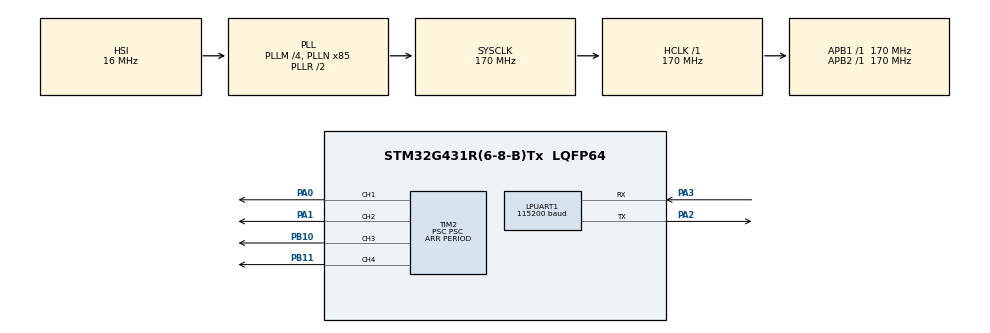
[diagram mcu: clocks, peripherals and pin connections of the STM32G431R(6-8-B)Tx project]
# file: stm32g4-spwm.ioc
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Dma.LPUART1_RX.1.Direction=DMA_PERIPH_TO_MEMORY
Dma.LPUART1_RX.1.EventEnable=DISABLE
Dma.LPUART1_RX.1.Instance=DMA1_Channel2
Dma.LPUART1_RX.1.MemDataAlignment=DMA_MDATAALIGN_BYTE
Dma.LPUART1_RX.1.MemInc=DMA_MINC_ENABLE
Dma.LPUART1_RX.1.Mode=DMA_NORMAL
Dma.LPUART1_RX.1.PeriphDataAlignment=DMA_PDATAALIGN_BYTE
Dma.LPUART1_RX.1.PeriphInc=DMA_PINC_DISABLE
Dma.LPUART1_RX.1.Polarity=HAL_DMAMUX_REQ_GEN_RISING
Dma.LPUART1_RX.1.Priority=DMA_PRIORITY_MEDIUM
Dma.LPUART1_RX.1.RequestNumber=1
Dma.LPUART1_RX.1.SignalID=NONE
Dma.LPUART1_RX.1.SyncEnable=DISABLE
Dma.LPUART1_RX.1.SyncPolarity=HAL_DMAMUX_SYNC_NO_EVENT
Dma.LPUART1_RX.1.SyncRequestNumber=1
Dma.LPUART1_RX.1.SyncSignalID=NONE
Dma.LPUART1_TX.2.Direction=DMA_MEMORY_TO_PERIPH
Dma.LPUART1_TX.2.EventEnable=DISABLE
Dma.LPUART1_TX.2.Instance=DMA1_Channel3
Dma.LPUART1_TX.2.MemDataAlignment=DMA_MDATAALIGN_BYTE
Dma.LPUART1_TX.2.MemInc=DMA_MINC_ENABLE
Dma.LPUART1_TX.2.Mode=DMA_NORMAL
Dma.LPUART1_TX.2.PeriphDataAlignment=DMA_PDATAALIGN_BYTE
Dma.LPUART1_TX.2.PeriphInc=DMA_PINC_DISABLE
Dma.LPUART1_TX.2.Polarity=HAL_DMAMUX_REQ_GEN_RISING
Dma.LPUART1_TX.2.Priority=DMA_PRIORITY_MEDIUM
Dma.LPUART1_TX.2.RequestNumber=1
Dma.LPUART1_TX.2.SignalID=NONE
Dma.LPUART1_TX.2.SyncEnable=DISABLE
Dma.LPUART1_TX.2.SyncPolarity=HAL_DMAMUX_SYNC_NO_EVENT
Dma.LPUART1_TX.2.SyncRequestNumber=1
Dma.LPUART1_TX.2.SyncSignalID=NONE
Dma.Request0=TIM2_UP
Dma.Request1=LPUART1_RX
Dma.Request2=LPUART1_TX
Dma.TIM2_UP.0.Direction=DMA_MEMORY_TO_PERIPH
Dma.TIM2_UP.0.EventEnable=DISABLE
Dma.TIM2_UP.0.Instance=DMA1_Channel1
Dma.TIM2_UP.0.MemDataAlignment=DMA_MDATAALIGN_WORD
Dma.TIM2_UP.0.MemInc=DMA_MINC_ENABLE
Dma.TIM2_UP.0.Mode=DMA_CIRCULAR
Dma.TIM2_UP.0.PeriphDataAlignment=DMA_PDATAALIGN_WORD
Dma.TIM2_UP.0.PeriphInc=DMA_PINC_DISABLE
Dma.TIM2_UP.0.Polarity=HAL_DMAMUX_REQ_GEN_RISING
Dma.TIM2_UP.0.Priority=DMA_PRIORITY_MEDIUM
Dma.TIM2_UP.0.RequestNumber=1
Dma.TIM2_UP.0.SignalID=NONE
Dma.TIM2_UP.0.SyncEnable=DISABLE
Dma.TIM2_UP.0.SyncPolarity=HAL_DMAMUX_SYNC_NO_EVENT
Dma.TIM2_UP.0.SyncRequestNumber=1
Dma.TIM2_UP.0.SyncSignalID=NONE
LPUART1.BaudRate=115200
Mcu.Family=STM32G4
Mcu.Name=STM32G431R(6-8-B)Tx
Mcu.Package=LQFP64
NVIC.DMA1_Channel1_IRQn=true\:0\:0\:false\:false\:true\:false\:true\:true
NVIC.DMA1_Channel2_IRQn=true\:0\:0\:false\:false\:true\:false\:true\:true
NVIC.DMA1_Channel3_IRQn=true\:0\:0\:false\:false\:true\:false\:true\:true
NVIC.LPUART1_IRQn=true\:0\:0\:false\:false\:true\:true\:true\:true
NVIC.PriorityGroup=NVIC_PRIORITYGROUP_4
NVIC.TIM2_IRQn=true\:0\:0\:false\:false\:true\:true\:true\:true
PA0.GPIO_Speed=GPIO_SPEED_FREQ_HIGH
PA0.Signal=S_TIM2_CH1
PA1.GPIO_Speed=GPIO_SPEED_FREQ_HIGH
PA1.Signal=S_TIM2_CH2
PA13.Mode=Serial_Wire
PA13.Signal=SYS_JTMS-SWDIO
PA14.Mode=Serial_Wire
PA14.Signal=SYS_JTCK-SWCLK
PA2.GPIO_Speed=GPIO_SPEED_FREQ_MEDIUM
PA2.Mode=Asynchronous
PA2.Signal=LPUART1_TX
PA3.GPIO_Speed=GPIO_SPEED_FREQ_MEDIUM
PA3.Mode=Asynchronous
PA3.Signal=LPUART1_RX
PB10.GPIO_Speed=GPIO_SPEED_FREQ_HIGH
PB10.Signal=S_TIM2_CH3
PB11.GPIO_Speed=GPIO_SPEED_FREQ_HIGH
PB11.Signal=S_TIM2_CH4
PF0-OSC_IN.Mode=HSE-External-Oscillator
PF0-OSC_IN.Signal=RCC_OSC_IN
PF1-OSC_OUT.Mode=HSE-External-Oscillator
PF1-OSC_OUT.Signal=RCC_OSC_OUT
ProjectManager.HeapSize=0x200
ProjectManager.StackSize=0x400
ProjectManager.TargetToolchain=CMake
RCC.ADC12Freq_Value=170000000
RCC.AHBFreq_Value=170000000
RCC.APB1Freq_Value=170000000
RCC.APB1TimFreq_Value=170000000
RCC.APB2Freq_Value=170000000
RCC.APB2TimFreq_Value=170000000
RCC.CortexFreq_Value=170000000
RCC.EXTERNAL_CLOCK_VALUE=12288000
RCC.HCLKFreq_Value=170000000
RCC.HSE_VALUE=8000000
RCC.HSI48_VALUE=48000000
RCC.HSI_VALUE=16000000
RCC.LSE_VALUE=32768
RCC.PLLM=RCC_PLLM_DIV4
RCC.PLLN=85
RCC.SYSCLKFreq_VALUE=170000000
RCC.SYSCLKSource=RCC_SYSCLKSOURCE_PLLCLK
RCC.USBFreq_Value=170000000
RCC.VCOOutputFreq_Value=340000000
SH.S_TIM2_CH1.0=TIM2_CH1,PWM Generation1 CH1
SH.S_TIM2_CH2.0=TIM2_CH2,PWM Generation2 CH2
SH.S_TIM2_CH3.0=TIM2_CH3,PWM Generation3 CH3
SH.S_TIM2_CH4.0=TIM2_CH4,PWM Generation4 CH4
TIM2.Channel-PWM\ Generation1\ CH1=TIM_CHANNEL_1
TIM2.Channel-PWM\ Generation2\ CH2=TIM_CHANNEL_2
TIM2.Channel-PWM\ Generation3\ CH3=TIM_CHANNEL_3
TIM2.Channel-PWM\ Generation4\ CH4=TIM_CHANNEL_4
TIM2.OCFastMode_PWM-PWM\ Generation1\ CH1=TIM_OCFAST_ENABLE
TIM2.OCFastMode_PWM-PWM\ Generation2\ CH2=TIM_OCFAST_ENABLE
TIM2.OCFastMode_PWM-PWM\ Generation3\ CH3=TIM_OCFAST_ENABLE
TIM2.OCFastMode_PWM-PWM\ Generation4\ CH4=TIM_OCFAST_ENABLE
TIM2.PeriodNoDither=PERIOD
TIM2.Prescaler=PSC
VP_SYS_VS_DBSignals.Mode=DisableDeadBatterySignals
VP_TIM2_VS_ClockSourceINT.Mode=Internal
board=custom

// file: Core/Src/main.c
/* USER CODE BEGIN Header */
/**
  ******************************************************************************
  * @file           : main.c
  * @brief          : Main program body
  ******************************************************************************
  * @attention
  *
  * Copyright (c) 2026 STMicroelectronics.
  * All rights reserved.
  *
  * This software is licensed under terms that can be found in the LICENSE file
  * in the root directory of this software component.
  * If no LICENSE file comes with this software, it is provided AS-IS.
  *
  ******************************************************************************
  */
/* USER CODE END Header */
#include "main.h"

/* USER CODE BEGIN PTD */
#define PSC 1
#define PERIOD 100

/* USER CODE END PTD */

UART_HandleTypeDef hlpuart1;
DMA_HandleTypeDef hdma_lpuart1_rx;
DMA_HandleTypeDef hdma_lpuart1_tx;

TIM_HandleTypeDef htim2;
DMA_HandleTypeDef hdma_tim2_up;

void SystemClock_Config(void);
static void MX_GPIO_Init(void);
static void MX_DMA_Init(void);
static void MX_TIM2_Init(void);
static void MX_LPUART1_UART_Init(void);

int main(void)
{

  /* MCU Configuration--------------------------------------------------------*/

  /* Reset of all peripherals, Initializes the Flash interface and the Systick. */
  HAL_Init();

  /* Configure the system clock */
  SystemClock_Config();

  /* Initialize all configured peripherals */
  MX_GPIO_Init();
  MX_DMA_Init();
  MX_TIM2_Init();
  MX_LPUART1_UART_Init();

  /* Infinite loop */
  while (1)
  {

  }
}

void SystemClock_Config(void)
{
  RCC_OscInitTypeDef RCC_OscInitStruct = {0};
  RCC_ClkInitTypeDef RCC_ClkInitStruct = {0};

  /** Configure the main internal regulator output voltage
  */
  HAL_PWREx_ControlVoltageScaling(PWR_REGULATOR_VOLTAGE_SCALE1_BOOST);

  /** Initializes the RCC Oscillators according to the specified parameters
  * in the RCC_OscInitTypeDef structure.
  */
  RCC_OscInitStruct.OscillatorType = RCC_OSCILLATORTYPE_HSI;
  RCC_OscInitStruct.HSIState = RCC_HSI_ON;
  RCC_OscInitStruct.HSICalibrationValue = RCC_HSICALIBRATION_DEFAULT;
  RCC_OscInitStruct.PLL.PLLState = RCC_PLL_ON;
  RCC_OscInitStruct.PLL.PLLSource = RCC_PLLSOURCE_HSI;
  RCC_OscInitStruct.PLL.PLLM = RCC_PLLM_DIV4;
  RCC_OscInitStruct.PLL.PLLN = 85;
  RCC_OscInitStruct.PLL.PLLP = RCC_PLLP_DIV2;
  RCC_OscInitStruct.PLL.PLLQ = RCC_PLLQ_DIV2;
  RCC_OscInitStruct.PLL.PLLR = RCC_PLLR_DIV2;
  if (HAL_RCC_OscConfig(&RCC_OscInitStruct) != HAL_OK)
  {
    Error_Handler();
  }

  /** Initializes the CPU, AHB and APB buses clocks
  */
  RCC_ClkInitStruct.ClockType = RCC_CLOCKTYPE_HCLK|RCC_CLOCKTYPE_SYSCLK
                              |RCC_CLOCKTYPE_PCLK1|RCC_CLOCKTYPE_PCLK2;
  RCC_ClkInitStruct.SYSCLKSource = RCC_SYSCLKSOURCE_PLLCLK;
  RCC_ClkInitStruct.AHBCLKDivider = RCC_SYSCLK_DIV1;
  RCC_ClkInitStruct.APB1CLKDivider = RCC_HCLK_DIV1;
  RCC_ClkInitStruct.APB2CLKDivider = RCC_HCLK_DIV1;

  if (HAL_RCC_ClockConfig(&RCC_ClkInitStruct, FLASH_LATENCY_4) != HAL_OK)
  {
    Error_Handler();
  }
}

static void MX_LPUART1_UART_Init(void)
{

  hlpuart1.Instance = LPUART1;
  hlpuart1.Init.BaudRate = 115200;
  hlpuart1.Init.WordLength = UART_WORDLENGTH_8B;
  hlpuart1.Init.StopBits = UART_STOPBITS_1;
  hlpuart1.Init.Parity = UART_PARITY_NONE;
  hlpuart1.Init.Mode = UART_MODE_TX_RX;
  hlpuart1.Init.HwFlowCtl = UART_HWCONTROL_NONE;
  hlpuart1.Init.OneBitSampling = UART_ONE_BIT_SAMPLE_DISABLE;
  hlpuart1.Init.ClockPrescaler = UART_PRESCALER_DIV1;
  hlpuart1.AdvancedInit.AdvFeatureInit = UART_ADVFEATURE_NO_INIT;
  if (HAL_UART_Init(&hlpuart1) != HAL_OK)
  {
    Error_Handler();
  }
  if (HAL_UARTEx_SetTxFifoThreshold(&hlpuart1, UART_TXFIFO_THRESHOLD_1_8) != HAL_OK)
  {
    Error_Handler();
  }
  if (HAL_UARTEx_SetRxFifoThreshold(&hlpuart1, UART_RXFIFO_THRESHOLD_1_8) != HAL_OK)
  {
    Error_Handler();
  }
  if (HAL_UARTEx_DisableFifoMode(&hlpuart1) != HAL_OK)
  {
    Error_Handler();
  }

}

static void MX_TIM2_Init(void)
{

  TIM_ClockConfigTypeDef sClockSourceConfig = {0};
  TIM_MasterConfigTypeDef sMasterConfig = {0};
  TIM_OC_InitTypeDef sConfigOC = {0};

  htim2.Instance = TIM2;
  htim2.Init.Prescaler = PSC;
  htim2.Init.CounterMode = TIM_COUNTERMODE_UP;
  htim2.Init.Period = PERIOD;
  htim2.Init.ClockDivision = TIM_CLOCKDIVISION_DIV1;
  htim2.Init.AutoReloadPreload = TIM_AUTORELOAD_PRELOAD_DISABLE;
  if (HAL_TIM_Base_Init(&htim2) != HAL_OK)
  {
    Error_Handler();
  }
  sClockSourceConfig.ClockSource = TIM_CLOCKSOURCE_INTERNAL;
  if (HAL_TIM_ConfigClockSource(&htim2, &sClockSourceConfig) != HAL_OK)
  {
    Error_Handler();
  }
  if (HAL_TIM_PWM_Init(&htim2) != HAL_OK)
  {
    Error_Handler();
  }
  sMasterConfig.MasterOutputTrigger = TIM_TRGO_RESET;
  sMasterConfig.MasterSlaveMode = TIM_MASTERSLAVEMODE_DISABLE;
  if (HAL_TIMEx_MasterConfigSynchronization(&htim2, &sMasterConfig) != HAL_OK)
  {
    Error_Handler();
  }
  sConfigOC.OCMode = TIM_OCMODE_PWM1;
  sConfigOC.Pulse = 0;
  sConfigOC.OCPolarity = TIM_OCPOLARITY_HIGH;
  sConfigOC.OCFastMode = TIM_OCFAST_ENABLE;
  if (HAL_TIM_PWM_ConfigChannel(&htim2, &sConfigOC, TIM_CHANNEL_1) != HAL_OK)
  {
    Error_Handler();
  }
  if (HAL_TIM_PWM_ConfigChannel(&htim2, &sConfigOC, TIM_CHANNEL_2) != HAL_OK)
  {
    Error_Handler();
  }
  if (HAL_TIM_PWM_ConfigChannel(&htim2, &sConfigOC, TIM_CHANNEL_3) != HAL_OK)
  {
    Error_Handler();
  }
  if (HAL_TIM_PWM_ConfigChannel(&htim2, &sConfigOC, TIM_CHANNEL_4) != HAL_OK)
  {
    Error_Handler();
  }
  HAL_TIM_MspPostInit(&htim2);

}

static void MX_DMA_Init(void)
{

  /* DMA controller clock enable */
  __HAL_RCC_DMAMUX1_CLK_ENABLE();
  __HAL_RCC_DMA1_CLK_ENABLE();

  /* DMA interrupt init */
  /* DMA1_Channel1_IRQn interrupt configuration */
  HAL_NVIC_SetPriority(DMA1_Channel1_IRQn, 0, 0);
  HAL_NVIC_EnableIRQ(DMA1_Channel1_IRQn);
  /* DMA1_Channel2_IRQn interrupt configuration */
  HAL_NVIC_SetPriority(DMA1_Channel2_IRQn, 0, 0);
  HAL_NVIC_EnableIRQ(DMA1_Channel2_IRQn);
  /* DMA1_Channel3_IRQn interrupt configuration */
  HAL_NVIC_SetPriority(DMA1_Channel3_IRQn, 0, 0);
  HAL_NVIC_EnableIRQ(DMA1_Channel3_IRQn);

}

static void MX_GPIO_Init(void)
{

  /* GPIO Ports Clock Enable */
  __HAL_RCC_GPIOF_CLK_ENABLE();
  __HAL_RCC_GPIOA_CLK_ENABLE();
  __HAL_RCC_GPIOB_CLK_ENABLE();

}

void Error_Handler(void)
{
  __disable_irq();
  while (1)
  {
  }
}
